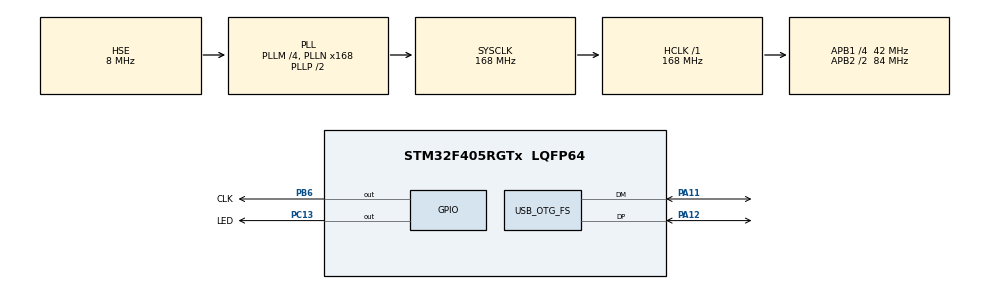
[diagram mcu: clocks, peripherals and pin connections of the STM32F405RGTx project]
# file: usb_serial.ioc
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Mcu.Family=STM32F4
USB_DEVICE.CLASS_NAME_FS=CDC
PH0-OSC_IN.Signal=RCC_OSC_IN
RCC.CortexFreq_Value=168000000
USB_DEVICE.VirtualModeFS=Cdc_FS
PC13-ANTI_TAMP.GPIO_Label=LED
PA11.Mode=Device_Only
PB6.GPIO_Label=CLK
USB_DEVICE.VirtualMode-CDC_FS=Cdc
RCC.APB1CLKDivider=RCC_HCLK_DIV4
TIM4.TIM_MasterOutputTrigger=TIM_TRGO_UPDATE
PC13-ANTI_TAMP.PinState=GPIO_PIN_SET
RCC.SYSCLKSource=RCC_SYSCLKSOURCE_PLLCLK
ProjectManager.StackSize=0x400
PA13.Signal=SYS_JTMS-SWDIO
PA12.Signal=USB_OTG_FS_DP
ProjectManager.TargetToolchain=STM32CubeIDE
USB_DEVICE.PRODUCT_STRING_CDC_FS=Virtual ComPort
RCC.HCLKFreq_Value=168000000
VP_USB_DEVICE_VS_USB_DEVICE_CDC_FS.Mode=CDC_FS
RCC.APB2TimFreq_Value=168000000
PB6.Signal=GPIO_Output
TIM4.Prescaler=83
RCC.LSE_VALUE=32768
RCC.AHBFreq_Value=168000000
PH0-OSC_IN.Mode=HSE-External-Oscillator
RCC.HSE_VALUE=8000000
board=custom
PC13-ANTI_TAMP.Signal=GPIO_Output
RCC.VCOOutputFreq_Value=336000000
PC13-ANTI_TAMP.GPIO_ModeDefaultOutputPP=GPIO_MODE_OUTPUT_OD
RCC.APB2Freq_Value=84000000
PA14.Mode=Serial_Wire
USB_DEVICE.MANUFACTURER_STRING-CDC_FS=lbthomsen
PH1-OSC_OUT.Signal=RCC_OSC_OUT
USB_OTG_FS.Sof_enable=ENABLE
TIM4.Period=99
PA13.Mode=Serial_Wire
Mcu.Name=STM32F405RGTx
PH1-OSC_OUT.Mode=HSE-External-Oscillator
RCC.48MHZClocksFreq_Value=48000000
RCC.SYSCLKFreq_VALUE=168000000
Mcu.Package=LQFP64
PA12.Mode=Device_Only
NVIC.OTG_FS_IRQn=true\:0\:0\:false\:false\:true\:false\:true
PA11.Signal=USB_OTG_FS_DM
PA14.Signal=SYS_JTCK-SWCLK
USB_OTG_FS.VirtualMode=Device_Only
ProjectManager.HeapSize=0x200
RCC.HSI_VALUE=16000000
VP_TIM4_VS_ClockSourceINT.Mode=Internal
RCC.PLLQ=7
NVIC.PriorityGroup=NVIC_PRIORITYGROUP_4
RCC.APB2CLKDivider=RCC_HCLK_DIV2
RCC.PLLM=4
RCC.PLLN=168
RCC.APB1TimFreq_Value=84000000
NVIC.TIM4_IRQn=true\:0\:0\:false\:false\:true\:true\:true
RCC.APB1Freq_Value=42000000

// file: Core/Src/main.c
/* USER CODE BEGIN Header */
/**
  ******************************************************************************
  * @file           : main.c
  * @brief          : Main program body
  ******************************************************************************
  * @attention
  *
  * <h2><center>&copy; Copyright (c) 2020 Lars Boegild Thomsen <lbthomsen@gmail.com>
  * All rights reserved.</center></h2>
  *
  * This software component is licensed by lbthomsen under MIT license,
  * the "License"; You may not use this file except in compliance with the
  * License. You may obtain a copy of the License at:
  *                        opensource.org/licenses/MIT
  *
  ******************************************************************************
  */
/* USER CODE END Header */
#include "main.h"
#include "usb_device.h"

/* USER CODE BEGIN Includes */
#include "stdio.h"
#include "usbd_cdc_if.h"
/* USER CODE END Includes */

TIM_HandleTypeDef htim4;

void SystemClock_Config(void);
static void MX_GPIO_Init(void);
static void MX_TIM4_Init(void);

/* USER CODE BEGIN 0 */
// Override the weak call back function
void HAL_TIM_PeriodElapsedCallback(TIM_HandleTypeDef *htim) {
      if (htim->Instance == TIM4) {
              HAL_GPIO_TogglePin(CLK_GPIO_Port, CLK_Pin);
      }
}
/* USER CODE END 0 */

int main(void)
{

  /* MCU Configuration--------------------------------------------------------*/

  /* Reset of all peripherals, Initializes the Flash interface and the Systick. */
  HAL_Init();

  /* Configure the system clock */
  SystemClock_Config();

  /* Initialize all configured peripherals */
  MX_GPIO_Init();
  MX_USB_DEVICE_Init();
  MX_TIM4_Init();
  /* USER CODE BEGIN 2 */

  HAL_TIM_Base_Start_IT(&htim4);

  /* USER CODE END 2 */

  /* Infinite loop */
  /* USER CODE BEGIN WHILE */

  uint32_t then = 0; // Used in main loop

  while (1)
  {

	uint32_t now = HAL_GetTick();
	if (now % 1000 == 0 && now != then) {

		HAL_GPIO_TogglePin(LED_GPIO_Port, LED_Pin);

		uint8_t buffer[] = "Hello, Cruel World!\r\n";
		CDC_Transmit_FS(buffer, sizeof(buffer));

		//printf("Now: %l\n", now);

		then = now;
	}

    /* USER CODE END WHILE */

  }
}

void SystemClock_Config(void)
{
  RCC_OscInitTypeDef RCC_OscInitStruct = {0};
  RCC_ClkInitTypeDef RCC_ClkInitStruct = {0};

  /** Configure the main internal regulator output voltage
  */
  __HAL_RCC_PWR_CLK_ENABLE();
  __HAL_PWR_VOLTAGESCALING_CONFIG(PWR_REGULATOR_VOLTAGE_SCALE1);
  /** Initializes the RCC Oscillators according to the specified parameters
  * in the RCC_OscInitTypeDef structure.
  */
  RCC_OscInitStruct.OscillatorType = RCC_OSCILLATORTYPE_HSE;
  RCC_OscInitStruct.HSEState = RCC_HSE_ON;
  RCC_OscInitStruct.PLL.PLLState = RCC_PLL_ON;
  RCC_OscInitStruct.PLL.PLLSource = RCC_PLLSOURCE_HSE;
  RCC_OscInitStruct.PLL.PLLM = 4;
  RCC_OscInitStruct.PLL.PLLN = 168;
  RCC_OscInitStruct.PLL.PLLP = RCC_PLLP_DIV2;
  RCC_OscInitStruct.PLL.PLLQ = 7;
  if (HAL_RCC_OscConfig(&RCC_OscInitStruct) != HAL_OK)
  {
    Error_Handler();
  }
  /** Initializes the CPU, AHB and APB buses clocks
  */
  RCC_ClkInitStruct.ClockType = RCC_CLOCKTYPE_HCLK|RCC_CLOCKTYPE_SYSCLK
                              |RCC_CLOCKTYPE_PCLK1|RCC_CLOCKTYPE_PCLK2;
  RCC_ClkInitStruct.SYSCLKSource = RCC_SYSCLKSOURCE_PLLCLK;
  RCC_ClkInitStruct.AHBCLKDivider = RCC_SYSCLK_DIV1;
  RCC_ClkInitStruct.APB1CLKDivider = RCC_HCLK_DIV4;
  RCC_ClkInitStruct.APB2CLKDivider = RCC_HCLK_DIV2;

  if (HAL_RCC_ClockConfig(&RCC_ClkInitStruct, FLASH_LATENCY_5) != HAL_OK)
  {
    Error_Handler();
  }
}

static void MX_TIM4_Init(void)
{

  TIM_ClockConfigTypeDef sClockSourceConfig = {0};
  TIM_MasterConfigTypeDef sMasterConfig = {0};

  htim4.Instance = TIM4;
  htim4.Init.Prescaler = 83;
  htim4.Init.CounterMode = TIM_COUNTERMODE_UP;
  htim4.Init.Period = 99;
  htim4.Init.ClockDivision = TIM_CLOCKDIVISION_DIV1;
  htim4.Init.AutoReloadPreload = TIM_AUTORELOAD_PRELOAD_DISABLE;
  if (HAL_TIM_Base_Init(&htim4) != HAL_OK)
  {
    Error_Handler();
  }
  sClockSourceConfig.ClockSource = TIM_CLOCKSOURCE_INTERNAL;
  if (HAL_TIM_ConfigClockSource(&htim4, &sClockSourceConfig) != HAL_OK)
  {
    Error_Handler();
  }
  sMasterConfig.MasterOutputTrigger = TIM_TRGO_UPDATE;
  sMasterConfig.MasterSlaveMode = TIM_MASTERSLAVEMODE_DISABLE;
  if (HAL_TIMEx_MasterConfigSynchronization(&htim4, &sMasterConfig) != HAL_OK)
  {
    Error_Handler();
  }

}

static void MX_GPIO_Init(void)
{
  GPIO_InitTypeDef GPIO_InitStruct = {0};

  /* GPIO Ports Clock Enable */
  __HAL_RCC_GPIOC_CLK_ENABLE();
  __HAL_RCC_GPIOH_CLK_ENABLE();
  __HAL_RCC_GPIOA_CLK_ENABLE();
  __HAL_RCC_GPIOB_CLK_ENABLE();

  /*Configure GPIO pin Output Level */
  HAL_GPIO_WritePin(LED_GPIO_Port, LED_Pin, GPIO_PIN_SET);

  /*Configure GPIO pin Output Level */
  HAL_GPIO_WritePin(CLK_GPIO_Port, CLK_Pin, GPIO_PIN_RESET);

  /*Configure GPIO pin : LED_Pin */
  GPIO_InitStruct.Pin = LED_Pin;
  GPIO_InitStruct.Mode = GPIO_MODE_OUTPUT_OD;
  GPIO_InitStruct.Pull = GPIO_NOPULL;
  GPIO_InitStruct.Speed = GPIO_SPEED_FREQ_LOW;
  HAL_GPIO_Init(LED_GPIO_Port, &GPIO_InitStruct);

  /*Configure GPIO pin : CLK_Pin */
  GPIO_InitStruct.Pin = CLK_Pin;
  GPIO_InitStruct.Mode = GPIO_MODE_OUTPUT_PP;
  GPIO_InitStruct.Pull = GPIO_NOPULL;
  GPIO_InitStruct.Speed = GPIO_SPEED_FREQ_LOW;
  HAL_GPIO_Init(CLK_GPIO_Port, &GPIO_InitStruct);

}

void Error_Handler(void)
{
}

/************************ (C) COPYRIGHT STMicroelectronics *****END OF FILE****/
